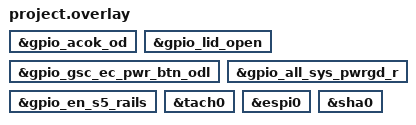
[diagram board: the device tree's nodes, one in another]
/* Copyright 2025 The ChromiumOS Authors
 * Use of this source code is governed by a BSD-style license that can be
 * found in the LICENSE file.
 */

/* ocelot program common DTS includes */

#include <cros/integrated_fwid.dtsi>

/* ocicat project DTS includes */

#include "binman.dtsi"
#include "gpios.dtsi"
#include "power_signals.dtsi"






/*
 * Map GPIOs used for interrupts to common names
 */

gpio_acok: &gpio_acok_od {};
gpio_lid: &gpio_lid_open {};
gpio_pwrbtn: &gpio_gsc_ec_pwr_btn_odl {};
gpio_all_sys_pwr_good: &gpio_all_sys_pwrgd_r {};
gpio_temp_sensor_power_good: &gpio_en_s5_rails {};

/* Map tachometers to common names */
tach_fan0: &tach0 {};

#include "cbi.dtsi"
#include "adc.dtsi"
#include "battery.dtsi"
#include "console.dtsi"
#include "fan.dtsi"
#include "i2c.dtsi"
#include "interrupts.dtsi"
#include "keyboard.dtsi"
#include "pwm.dtsi"
#include "usba.dtsi"
#include "usb_typec.dtsi"

#include "../ite_hibernate.dtsi"


&espi0 {
	status = "okay";
};

&sha0 {
	status = "okay";
};

